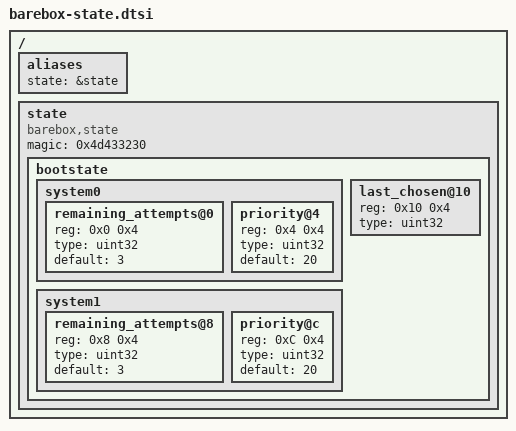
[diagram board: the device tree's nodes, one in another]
/ {
	aliases {
		state = &state;
	};

	/* State: mutable part */
	state: state {
		magic = <0x4d433230>;
		compatible = "barebox,state";

		bootstate {
			#address-cells = <1>;
			#size-cells = <1>;

			system0 { /* the node's name here must match the subnode's name in the 'bootstate' node */
				#address-cells = <1>;
				#size-cells = <1>;

				remaining_attempts@0 {
					reg = <0x0 0x4>;
					type = "uint32";
					default = <3>;
				};
				priority@4 {
					reg = <0x4 0x4>;
					type = "uint32";
					default = <20>;
				};
			};

			system1 { /* the node's name here must match the subnode's name in the 'bootstate' node */
				#address-cells = <1>;
				#size-cells = <1>;

				remaining_attempts@8 {
					reg = <0x8 0x4>;
					type = "uint32";
					default = <3>;
				};
				priority@c {
					reg = <0xC 0x4>;
					type = "uint32";
					default = <20>;
				};
			};

			last_chosen@10 {
				reg = <0x10 0x4>;
				type = "uint32";
			};
		};
	};
};
